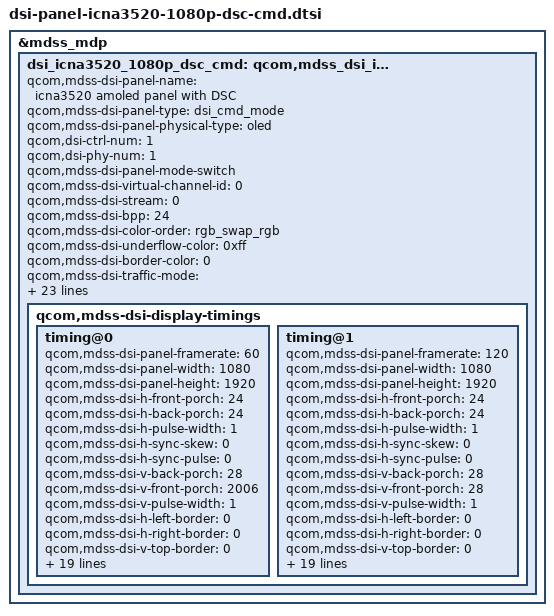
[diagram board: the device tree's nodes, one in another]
/* Copyright (c) 2016-2018, The Linux Foundation. All rights reserved.
 *
 * This program is free software; you can redistribute it and/or modify
 * it under the terms of the GNU General Public License version 2 and
 * only version 2 as published by the Free Software Foundation.
 *
 * This program is distributed in the hope that it will be useful,
 * but WITHOUT ANY WARRANTY; without even the implied warranty of
 * MERCHANTABILITY or FITNESS FOR A PARTICULAR PURPOSE.  See the
 * GNU General Public License for more details.
 */

&mdss_mdp {
	dsi_icna3520_1080p_dsc_cmd: qcom,mdss_dsi_icna3520_dsc_cmd {
		qcom,mdss-dsi-panel-name = "icna3520 amoled panel with DSC";
		qcom,mdss-dsi-panel-type = "dsi_cmd_mode";
		qcom,mdss-dsi-panel-physical-type = "oled";
		qcom,dsi-ctrl-num = <1>;
		qcom,dsi-phy-num = <1>;

		qcom,mdss-dsi-panel-mode-switch;

		qcom,mdss-dsi-virtual-channel-id = <0>;
		qcom,mdss-dsi-stream = <0>;
		qcom,mdss-dsi-bpp = <24>;
		qcom,mdss-dsi-color-order = "rgb_swap_rgb";
		qcom,mdss-dsi-underflow-color = <0xff>;
		qcom,mdss-dsi-border-color = <0>;

		qcom,mdss-dsi-traffic-mode = "non_burst_sync_event";
		qcom,mdss-dsi-lane-map = "lane_map_0123";
		qcom,mdss-dsi-bllp-eof-power-mode;
		qcom,mdss-dsi-bllp-power-mode;
		qcom,mdss-dsi-lane-0-state;
		qcom,mdss-dsi-lane-1-state;
		qcom,mdss-dsi-lane-2-state;
		qcom,mdss-dsi-lane-3-state;
		qcom,mdss-dsi-dma-trigger = "trigger_sw";
		qcom,mdss-dsi-mdp-trigger = "none";
		qcom,mdss-dsi-reset-sequence = <1 20>, <0 20>, <1 20>;
		qcom,mdss-dsi-te-pin-select = <1>;
		qcom,mdss-dsi-wr-mem-start = <0x2c>;
		qcom,mdss-dsi-wr-mem-continue = <0x3c>;
		qcom,mdss-dsi-te-dcs-command = <1>;
		qcom,mdss-dsi-te-check-enable;
		qcom,mdss-dsi-te-using-te-pin;
		qcom,mdss-dsi-force-clock-lane-hs;
		qcom,mdss-dsi-panel-hdr-enabled;
		qcom,mdss-dsi-panel-hdr-color-primaries = <14500 15500 32000
			17000 15500 30000 8000 3000>;
		qcom,mdss-dsi-panel-peak-brightness = <4200000>;
		qcom,mdss-dsi-panel-blackness-level = <3230>;

		qcom,mdss-dsi-display-timings {
			timing@0 {
				qcom,mdss-dsi-panel-framerate = <60>;
				qcom,mdss-dsi-panel-width = <1080>;
				qcom,mdss-dsi-panel-height = <1920>;
				qcom,mdss-dsi-h-front-porch = <24>;
				qcom,mdss-dsi-h-back-porch = <24>;
				qcom,mdss-dsi-h-pulse-width = <1>;
				qcom,mdss-dsi-h-sync-skew = <0>;
				qcom,mdss-dsi-h-sync-pulse = <0>;
				qcom,mdss-dsi-v-back-porch = <28>;
				qcom,mdss-dsi-v-front-porch = <2006>;
				qcom,mdss-dsi-v-pulse-width = <1>;
				qcom,mdss-dsi-h-left-border = <0>;
				qcom,mdss-dsi-h-right-border = <0>;
				qcom,mdss-dsi-v-top-border = <0>;
				qcom,mdss-dsi-v-bottom-border = <0>;
				qcom,mdss-dsi-panel-jitter = <0x3 0x1>;

				qcom,mdss-dsi-timing-switch-command = [
					39 01 00 00 00 00 02 48 10 // Write DSI MODE - HFR_MODE = HF1 Mode, DSI_MODE = Through GRAM
				];
				qcom,mdss-dsi-timing-switch-command-state = "dsi_lp_mode";

				qcom,mdss-dsi-on-command = [
					39 01 00 00 00 00 03 9C A5 A5 // User Command Access Unlock
					39 01 00 00 00 00 03 FD 5A 5A // Manufacture Command Access Unlock

					39 01 00 00 00 00 02 53 E0 // Write Control Display - HBM_MODE = HBM1, BCTL = On, BC_DIM_EN = Off, BC_DC_EN = Off, HBM_EN = Off
					05 01 00 00 00 00 01 35 // Tearing Effect Line On
					05 01 00 00 78 00 01 11 // Sleep Out

					39 01 00 00 00 00 02 9F 00 // REG SEL - Group 0
					39 01 00 00 00 00 0F B3 00 D8 00 1C 00 4C 00 00 DB 00 1C 07 D6 00 // Timing Control

					39 01 00 00 00 00 02 9F 01 // REG SEL - Group 1
					39 01 00 00 00 00 03 C0 1A 71
					39 01 00 00 00 00 21 C1 11 00 00 89 30 80 07 80 04 38 00 0C 02 1C 02 1C 02 00 02 0E 00 20 01 1F 00 07 00 0C 08 BB 08 7A
					39 01 00 00 00 00 21 C2 18 00 10 F0 03 0C 20 00 06 0B 0B 33 0E 1C 2A 38 46 54 62 69 70 77 79 7B 7D 7E 01 02 01 00 09 40
					39 01 00 00 00 00 19 C3 09 BE 19 FC 19 FA 19 F8 1A 38 1A 78 1A B6 2A F6 2B 34 2B 74 3B 74 6B F4
					39 01 00 00 00 00 02 B2 00

					39 01 00 00 00 00 02 9F 0D // REG SEL - Group 13
					39 01 00 00 00 00 02 B6 03
					39 01 00 00 00 00 02 BB 01
					39 01 00 00 00 00 02 B2 24

					39 01 00 00 00 00 03 FD A5 A5 // Manufacture Command Access Lock

					39 01 00 00 00 00 02 48 10 // Write DSI MODE - HFR_MODE = HF1 Mode, DSI_MODE = Through GRAM
					05 01 00 00 14 00 01 29 // Display On
				];
				qcom,mdss-dsi-on-command-state = "dsi_lp_mode";

				qcom,mdss-dsi-off-command = [
					05 01 00 00 14 00 02 28 00 // Display Off
					05 01 00 00 78 00 02 10 00 // Sleep In
				];
				qcom,mdss-dsi-off-command-state = "dsi_hs_mode";

				qcom,compression-mode = "dsc";
				qcom,mdss-dsc-slice-height = <12>;
				qcom,mdss-dsc-slice-width = <540>;
				qcom,mdss-dsc-slice-per-pkt = <2>;
				qcom,mdss-dsc-bit-per-component = <8>;
				qcom,mdss-dsc-bit-per-pixel = <8>;
				qcom,mdss-dsc-block-prediction-enable;
			};

			timing@1 {
				qcom,mdss-dsi-panel-framerate = <120>;
				qcom,mdss-dsi-panel-width = <1080>;
				qcom,mdss-dsi-panel-height = <1920>;
				qcom,mdss-dsi-h-front-porch = <24>;
				qcom,mdss-dsi-h-back-porch = <24>;
				qcom,mdss-dsi-h-pulse-width = <1>;
				qcom,mdss-dsi-h-sync-skew = <0>;
				qcom,mdss-dsi-h-sync-pulse = <0>;
				qcom,mdss-dsi-v-back-porch = <28>;
				qcom,mdss-dsi-v-front-porch = <28>;
				qcom,mdss-dsi-v-pulse-width = <1>;
				qcom,mdss-dsi-h-left-border = <0>;
				qcom,mdss-dsi-h-right-border = <0>;
				qcom,mdss-dsi-v-top-border = <0>;
				qcom,mdss-dsi-v-bottom-border = <0>;
				qcom,mdss-dsi-panel-jitter = <0x3 0x1>;

				qcom,mdss-dsi-timing-switch-command = [
					39 01 00 00 00 00 02 48 00 // Write DSI MODE - HFR_MODE = Normal Mode, DSI_MODE = Through GRAM
				];
				qcom,mdss-dsi-timing-switch-command-state = "dsi_lp_mode";

				qcom,mdss-dsi-on-command = [
					39 01 00 00 00 00 03 9C A5 A5 // User Command Access Unlock
					39 01 00 00 00 00 03 FD 5A 5A // Manufacture Command Access Unlock

					39 01 00 00 00 00 02 53 E0 // Write Control Display - HBM_MODE = HBM1, BCTL = On, BC_DIM_EN = Off, BC_DC_EN = Off, HBM_EN = Off
					05 01 00 00 00 00 01 35 // Tearing Effect Line On
					05 01 00 00 78 00 01 11 // Sleep Out

					39 01 00 00 00 00 02 9F 00 // REG SEL - Group 0
					39 01 00 00 00 00 0F B3 00 D8 00 1C 00 4C 00 00 DB 00 1C 07 D6 00 // Timing Control

					39 01 00 00 00 00 02 9F 01 // REG SEL - Group 1
					39 01 00 00 00 00 03 C0 1A 71
					39 01 00 00 00 00 21 C1 11 00 00 89 30 80 07 80 04 38 00 0C 02 1C 02 1C 02 00 02 0E 00 20 01 1F 00 07 00 0C 08 BB 08 7A
					39 01 00 00 00 00 21 C2 18 00 10 F0 03 0C 20 00 06 0B 0B 33 0E 1C 2A 38 46 54 62 69 70 77 79 7B 7D 7E 01 02 01 00 09 40
					39 01 00 00 00 00 19 C3 09 BE 19 FC 19 FA 19 F8 1A 38 1A 78 1A B6 2A F6 2B 34 2B 74 3B 74 6B F4
					39 01 00 00 00 00 02 B2 00

					39 01 00 00 00 00 02 9F 0D // REG SEL - Group 13
					39 01 00 00 00 00 02 B6 03
					39 01 00 00 00 00 02 BB 01
					39 01 00 00 00 00 02 B2 24

					39 01 00 00 00 00 03 FD A5 A5 // Manufacture Command Access Lock

					39 01 00 00 00 00 02 48 00 // Write DSI MODE - HFR_MODE = Normal Mode, DSI_MODE = Through GRAM
					05 01 00 00 14 00 01 29 // Display On
				];
				qcom,mdss-dsi-on-command-state = "dsi_lp_mode";

				qcom,mdss-dsi-off-command = [
					05 01 00 00 14 00 02 28 00 // Display Off
					05 01 00 00 78 00 02 10 00 // Sleep In
				];
				qcom,mdss-dsi-off-command-state = "dsi_hs_mode";

				qcom,compression-mode = "dsc";
				qcom,mdss-dsc-slice-height = <12>;
				qcom,mdss-dsc-slice-width = <540>;
				qcom,mdss-dsc-slice-per-pkt = <2>;
				qcom,mdss-dsc-bit-per-component = <8>;
				qcom,mdss-dsc-bit-per-pixel = <8>;
				qcom,mdss-dsc-block-prediction-enable;
			};
		};
	};
};
